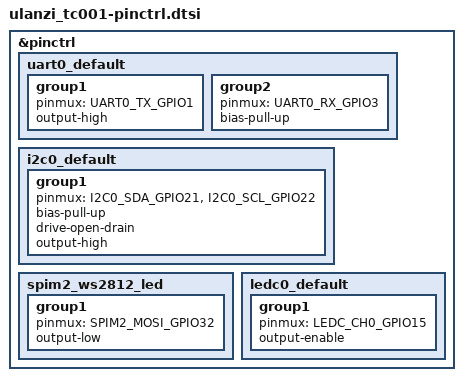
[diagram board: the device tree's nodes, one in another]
/*
 * Copyright (c) 2026 Bruno Vunderl
 *
 * SPDX-License-Identifier: Apache-2.0
 */

#include <zephyr/dt-bindings/pinctrl/esp32-pinctrl.h>

&pinctrl {
	uart0_default: uart0_default {
		group1 {
			pinmux = <UART0_TX_GPIO1>;
			output-high;
		};

		group2 {
			pinmux = <UART0_RX_GPIO3>;
			bias-pull-up;
		};
	};

	i2c0_default: i2c0_default {
		group1 {
			pinmux = <I2C0_SDA_GPIO21>,
				 <I2C0_SCL_GPIO22>;
			bias-pull-up;
			drive-open-drain;
			output-high;
		};
	};

	/* WS2812B matrix data line, driven from the SPI MOSI signal */
	spim2_ws2812_led: spim2_ws2812_led {
		group1 {
			pinmux = <SPIM2_MOSI_GPIO32>;
			output-low;
		};
	};

	ledc0_default: ledc0_default {
		group1 {
			pinmux = <LEDC_CH0_GPIO15>;
			output-enable;
		};
	};
};
